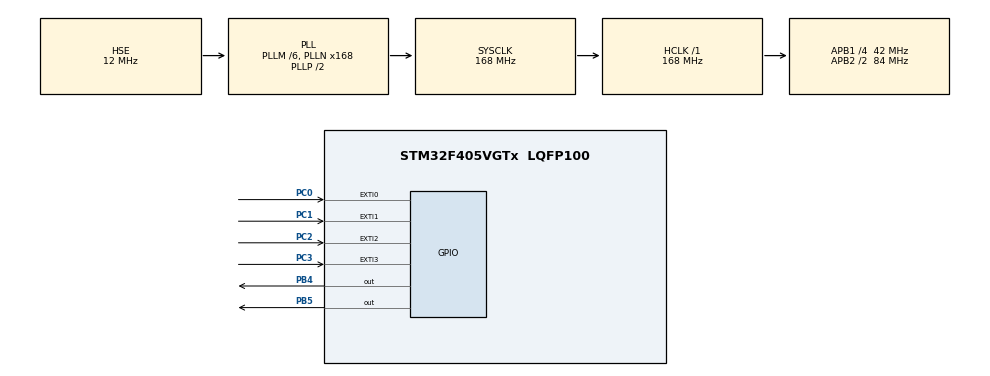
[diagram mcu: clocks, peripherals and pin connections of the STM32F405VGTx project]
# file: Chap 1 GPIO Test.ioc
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Mcu.Family=STM32F4
Mcu.Name=STM32F405VGTx
Mcu.Package=LQFP100
NVIC.EXTI0_IRQn=true\:0\:0\:false\:true\:true\:1\:true\:true\:true
NVIC.EXTI1_IRQn=true\:0\:0\:false\:true\:true\:2\:true\:true\:true
NVIC.EXTI2_IRQn=true\:0\:0\:false\:true\:true\:3\:true\:true\:true
NVIC.EXTI3_IRQn=true\:0\:0\:false\:true\:true\:4\:true\:true\:true
NVIC.PriorityGroup=NVIC_PRIORITYGROUP_4
PB4.Signal=GPIO_Output
PB5.Signal=GPIO_Output
PC0.Signal=GPXTI0
PC1.Signal=GPXTI1
PC2.Signal=GPXTI2
PC3.Signal=GPXTI3
PH0-OSC_IN.Mode=HSE-External-Oscillator
PH0-OSC_IN.Signal=RCC_OSC_IN
PH1-OSC_OUT.Mode=HSE-External-Oscillator
PH1-OSC_OUT.Signal=RCC_OSC_OUT
ProjectManager.HeapSize=0x200
ProjectManager.StackSize=0x400
ProjectManager.TargetToolchain=STM32CubeIDE
RCC.48MHZClocksFreq_Value=84000000
RCC.AHBFreq_Value=168000000
RCC.APB1CLKDivider=RCC_HCLK_DIV4
RCC.APB1Freq_Value=42000000
RCC.APB1TimFreq_Value=84000000
RCC.APB2CLKDivider=RCC_HCLK_DIV2
RCC.APB2Freq_Value=84000000
RCC.APB2TimFreq_Value=168000000
RCC.CortexFreq_Value=168000000
RCC.HCLKFreq_Value=168000000
RCC.HSE_VALUE=12000000
RCC.HSI_VALUE=16000000
RCC.LSE_VALUE=32768
RCC.PLLM=6
RCC.PLLN=168
RCC.PLLSourceVirtual=RCC_PLLSOURCE_HSE
RCC.SYSCLKFreq_VALUE=168000000
RCC.SYSCLKSource=RCC_SYSCLKSOURCE_PLLCLK
RCC.VCOOutputFreq_Value=336000000
board=custom

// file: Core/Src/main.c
/* USER CODE BEGIN Header */
/**
  ******************************************************************************
  * @file           : main.c
  * @brief          : Main program body
  ******************************************************************************
  * @attention
  *
  * Copyright (c) 2025 STMicroelectronics.
  * All rights reserved.
  *
  * This software is licensed under terms that can be found in the LICENSE file
  * in the root directory of this software component.
  * If no LICENSE file comes with this software, it is provided AS-IS.
  *
  ******************************************************************************
  */
/* USER CODE END Header */
#include "main.h"
#include "gpio.h"

void SystemClock_Config(void);
static void MX_NVIC_Init(void);

int main(void)
{

  /* MCU Configuration--------------------------------------------------------*/

  /* Reset of all peripherals, Initializes the Flash interface and the Systick. */
  HAL_Init();

  /* Configure the system clock */
  SystemClock_Config();

  /* Initialize all configured peripherals */
  MX_GPIO_Init();

  /* Initialize interrupts */
  MX_NVIC_Init();

  /* Infinite loop */
  while (1)
  {

  }
}

void SystemClock_Config(void)
{
  RCC_OscInitTypeDef RCC_OscInitStruct = {0};
  RCC_ClkInitTypeDef RCC_ClkInitStruct = {0};

  /** Configure the main internal regulator output voltage
  */
  __HAL_RCC_PWR_CLK_ENABLE();
  __HAL_PWR_VOLTAGESCALING_CONFIG(PWR_REGULATOR_VOLTAGE_SCALE1);

  /** Initializes the RCC Oscillators according to the specified parameters
  * in the RCC_OscInitTypeDef structure.
  */
  RCC_OscInitStruct.OscillatorType = RCC_OSCILLATORTYPE_HSE;
  RCC_OscInitStruct.HSEState = RCC_HSE_ON;
  RCC_OscInitStruct.PLL.PLLState = RCC_PLL_ON;
  RCC_OscInitStruct.PLL.PLLSource = RCC_PLLSOURCE_HSE;
  RCC_OscInitStruct.PLL.PLLM = 6;
  RCC_OscInitStruct.PLL.PLLN = 168;
  RCC_OscInitStruct.PLL.PLLP = RCC_PLLP_DIV2;
  RCC_OscInitStruct.PLL.PLLQ = 4;
  if (HAL_RCC_OscConfig(&RCC_OscInitStruct) != HAL_OK)
  {
    Error_Handler();
  }

  /** Initializes the CPU, AHB and APB buses clocks
  */
  RCC_ClkInitStruct.ClockType = RCC_CLOCKTYPE_HCLK|RCC_CLOCKTYPE_SYSCLK
                              |RCC_CLOCKTYPE_PCLK1|RCC_CLOCKTYPE_PCLK2;
  RCC_ClkInitStruct.SYSCLKSource = RCC_SYSCLKSOURCE_PLLCLK;
  RCC_ClkInitStruct.AHBCLKDivider = RCC_SYSCLK_DIV1;
  RCC_ClkInitStruct.APB1CLKDivider = RCC_HCLK_DIV4;
  RCC_ClkInitStruct.APB2CLKDivider = RCC_HCLK_DIV2;

  if (HAL_RCC_ClockConfig(&RCC_ClkInitStruct, FLASH_LATENCY_5) != HAL_OK)
  {
    Error_Handler();
  }
}

/**
  * @brief NVIC Configuration.
  * @retval None
  */
static void MX_NVIC_Init(void)
{
  /* EXTI0_IRQn interrupt configuration */
  HAL_NVIC_SetPriority(EXTI0_IRQn, 0, 0);
  HAL_NVIC_EnableIRQ(EXTI0_IRQn);
  /* EXTI1_IRQn interrupt configuration */
  HAL_NVIC_SetPriority(EXTI1_IRQn, 0, 0);
  HAL_NVIC_EnableIRQ(EXTI1_IRQn);
  /* EXTI2_IRQn interrupt configuration */
  HAL_NVIC_SetPriority(EXTI2_IRQn, 0, 0);
  HAL_NVIC_EnableIRQ(EXTI2_IRQn);
  /* EXTI3_IRQn interrupt configuration */
  HAL_NVIC_SetPriority(EXTI3_IRQn, 0, 0);
  HAL_NVIC_EnableIRQ(EXTI3_IRQn);
}

/* USER CODE BEGIN 4 */
void HAL_GPIO_EXTI_Callback(uint16_t GPIO_Pin)
{
    if(GPIO_Pin == GPIO_PIN_0) {

	}
	else if(GPIO_Pin == GPIO_PIN_1) {

	}
	else if(GPIO_Pin == GPIO_PIN_2) {

	}
	else if(GPIO_Pin == GPIO_PIN_3) {

	}
}

/* USER CODE END 4 */

void Error_Handler(void)
{
  __disable_irq();
  while (1)
  {
  }
}
